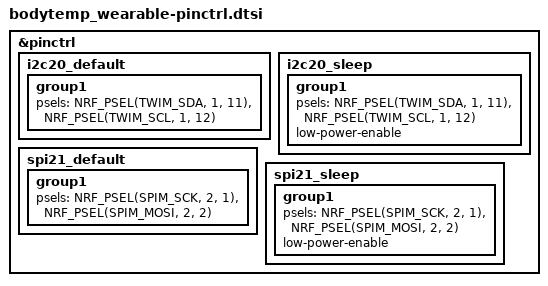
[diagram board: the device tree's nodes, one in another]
/*
 * ============================================================================
 *  File:    bodytemp_wearable-pinctrl.dtsi
 *  Purpose: Pin routing for the custom BodyTempSensor PCB.
 *  Author:  Daan
 *  Date:    2026-06-14
 *
 *  Description:
 *    Signal-to-pin mapping for the real PCB's nRF54L15. Mirrors the DK overlay
 *    structure but with the production pin choices. Every PSEL below must be
 *    confirmed against the KiCad schematic before the first board spin is
 *    flashed — these are scaffold values, not verified routing.
 *
 *  TODO(PoC): replace every pin number with the schematic-confirmed net.
 * ============================================================================
 */

&pinctrl {
	/* --- I2C20: TMP117 heat-flux bus --- */
	i2c20_default: i2c20_default {
		group1 {
			psels = <NRF_PSEL(TWIM_SDA, 1, 11)>,
				<NRF_PSEL(TWIM_SCL, 1, 12)>;
		};
	};
	i2c20_sleep: i2c20_sleep {
		group1 {
			psels = <NRF_PSEL(TWIM_SDA, 1, 11)>,
				<NRF_PSEL(TWIM_SCL, 1, 12)>;
			low-power-enable;
		};
	};

	/* --- SPI21: WS2812 status pixel data line --- */
	spi21_default: spi21_default {
		group1 {
			psels = <NRF_PSEL(SPIM_SCK,  2, 1)>,
				<NRF_PSEL(SPIM_MOSI, 2, 2)>;
		};
	};
	spi21_sleep: spi21_sleep {
		group1 {
			psels = <NRF_PSEL(SPIM_SCK,  2, 1)>,
				<NRF_PSEL(SPIM_MOSI, 2, 2)>;
			low-power-enable;
		};
	};
};
